AUTOSAR XML (schema 4-2-2)
# Copyright 2017 Mentor Graphics Corporation
# All rights reserved
# THIS WORK CONTAINS TRADE SECRET AND PROPRIETARY INFORMATION WHICH IS
# THE PROPERTY OF MENTOR GRAPHICS CORPORATION OR ITS LICENSORS AND IS
# SUBJECT TO LICENSE TERMS.
package /AUTOSAR/Services/Dem
  21 x client server interface, all with is-service=true:
    AgingCycle  # [SWS_Dem_00602]
      operation SetAgingCycleState: possible-error=AgingCycle/E_NOT_OK
      error E_NOT_OK: error-code=1
    CallbackClearEventAllowed  # [SWS_Dem_00620]
      operation ClearEventAllowed: possible-error=CallbackClearEventAllowed/E_NOT_OK
        arg Allowed: type=boolean, direction=OUT
      error E_NOT_OK: error-code=1
    CallbackDTCStatusChange  # [SWS_Dem_00617]
      operation DTCStatusChanged: possible-error=CallbackDTCStatusChange/E_NOT_OK
        arg DTC: type=uint32, direction=IN
        arg DTCStatusOld: type=Dem_UdsStatusByteType, direction=IN
        arg DTCStatusNew: type=Dem_UdsStatusByteType, direction=IN
      error E_NOT_OK: error-code=1
    CallbackEventDataChanged  # [SWS_Dem_00618]
      operation EventDataChanged
    CallbackEventStatusChange  # [SWS_Dem_00615]
      operation EventStatusChanged
        arg EventStatusByteOld: type=Dem_UdsStatusByteType, direction=IN
        arg EventStatusByteNew: type=Dem_UdsStatusByteType, direction=IN
    CallbackGetFaultDetectCounter  # [SWS_Dem_00622]
      operation GetFaultDetectionCounter: possible-error=CallbackGetFaultDetectCounter/E_NOT_OK
        arg FaultDetectionCounter: type=sint8, direction=OUT
      error E_NOT_OK: error-code=1
    CallbackInitMonitorForEvent  # [SWS_Dem_00613]
      operation InitMonitorForEvent: possible-error=CallbackInitMonitorForEvent/E_NOT_OK
        arg InitMonitorReason: type=Dem_InitMonitorReasonType, direction=IN
      error E_NOT_OK: error-code=1
    CddIf  # [SWS_Dem_00666]
      operation ClearDTC: possible-error=[CddIf/DEM_CLEAR_WRONG_DTC, CddIf/DEM_CLEAR_WRONG_DTCORIGIN, CddIf/DEM_CLEAR_FAILED, CddIf/DEM_CLEAR_PENDING, CddIf/DEM_CLEAR_BUSY, CddIf/DEM_CLEAR_MEMORY_ERROR]
        arg DTC: type=uint32, direction=IN
        arg DTCFormat: type=Dem_DTCFormatType, direction=IN
        arg DTCOrigin: type=Dem_DTCOriginType, direction=IN
      6 x error:
        DEM_CLEAR_WRONG_DTC: error-code=1
        DEM_CLEAR_WRONG_DTCORIGIN: error-code=2
        DEM_CLEAR_FAILED: error-code=3
        DEM_CLEAR_PENDING: error-code=4
        DEM_CLEAR_BUSY: error-code=5
        DEM_CLEAR_MEMORY_ERROR: error-code=6
    DcmIf  # [SWS_Dem_00609]
      operation DcmClearDTC: possible-error=[DcmIf/DEM_CLEAR_WRONG_DTC, DcmIf/DEM_CLEAR_WRONG_DTCORIGIN, DcmIf/DEM_CLEAR_FAILED, DcmIf/DEM_CLEAR_PENDING, DcmIf/DEM_CLEAR_BUSY, DcmIf/DEM_CLEAR_MEMORY_ERROR]
        arg DTC: type=uint32, direction=IN
        arg DTCFormat: type=Dem_DTCFormatType, direction=IN
        arg DTCOrigin: type=Dem_DTCOriginType, direction=IN
      operation DcmEnableDTCSetting: possible-error=[DEM_CONTROL_DTC_SETTING_N_OK, DEM_CONTROL_DTC_WRONG_DTCGROUP]
        arg DTCGroup: type=uint32, direction=IN
        arg DTCKind: type=Dem_DTCKindType, direction=IN
      8 x error:
        DEM_CLEAR_WRONG_DTC: error-code=1
        DEM_CLEAR_WRONG_DTCORIGIN: error-code=2
        DEM_CLEAR_FAILED: error-code=3
        DEM_CLEAR_PENDING: error-code=4
        DEM_CLEAR_BUSY: error-code=5
        DEM_CLEAR_MEMORY_ERROR: error-code=6
        DEM_CONTROL_DTC_SETTING_N_OK: error-code=1
        DEM_CONTROL_DTC_WRONG_DTCGROUP: error-code=2
    DiagnosticInfo  # [SWS_Dem_00599]
      7 x operation:
        GetEventExtendedDataRecord: possible-error=[DiagnosticInfo/E_NOT_OK, DiagnosticInfo/DEM_E_NODATAAVAILABLE, DiagnosticInfo/DEM_E_WRONG_RECORDNUMBER]
          arg RecordNumber: type=uint8, direction=IN
          arg DestBuffer: type=Dem_MaxDataValueType, direction=OUT, server-argument-impl-policy=USE-ARRAY-BASE-TYPE
        GetEventFreezeFrameData: possible-error=[DiagnosticInfo/E_NOT_OK, DiagnosticInfo/DEM_E_NODATAAVAILABLE, DiagnosticInfo/DEM_E_WRONG_RECORDNUMBER, DiagnosticInfo/DEM_E_WRONG_DIDNUMBER]
          4 x arg:
            RecordNumber: type=uint8, direction=IN
            ReportTotalRecord: type=boolean, direction=IN
            DataId: type=uint16, direction=IN
            DestBuffer: type=Dem_MaxDataValueType, direction=OUT, server-argument-impl-policy=USE-ARRAY-BASE-TYPE
        GetDTCOfEvent: possible-error=[DiagnosticInfo/E_NOT_OK, DiagnosticInfo/DEM_E_NO_DTC_AVAILABLE]
          arg DTCFormat: type=Dem_DTCFormatType, direction=IN
          arg DTCOfEvent: type=uint32, direction=OUT
        GetEventFailed: possible-error=DiagnosticInfo/E_NOT_OK
          arg EventFailed: type=boolean, direction=OUT
        GetEventStatus: possible-error=DiagnosticInfo/E_NOT_OK
          arg EventStatusByte: type=Dem_UdsStatusByteType, direction=OUT
        GetEventTested: possible-error=DiagnosticInfo/E_NOT_OK
          arg EventTested: type=boolean, direction=OUT
        GetFaultDetectionCounter: possible-error=[DiagnosticInfo/E_NOT_OK, DiagnosticInfo/DEM_E_NO_FDC_AVAILABLE]
          arg FaultDetectionCounter: type=sint8, direction=OUT
      6 x error:
        E_NOT_OK: error-code=1
        DEM_E_NO_DTC_AVAILABLE: error-code=2
        DEM_E_NO_FDC_AVAILABLE: error-code=3
        DEM_E_NODATAAVAILABLE: error-code=48
        DEM_E_WRONG_RECORDNUMBER: error-code=49
        DEM_E_WRONG_DIDNUMBER: error-code=50
    DiagnosticMonitor  # [SWS_Dem_00598]
      4 x operation, all with possible-error=DiagnosticMonitor/E_NOT_OK:
        SetEventStatus
          arg EventStatus: type=Dem_EventStatusType, direction=IN
        ResetEventStatus
        PrestoreFreezeFrame
        ClearPrestoredFreezeFrame
      error E_NOT_OK: error-code=1
    DTCSuppression  # [SWS_Dem_00608]
      operation SetDTCSuppression: possible-error=DTCSuppression/E_NOT_OK
        arg DTC: type=uint32, direction=IN
        arg DTCFormat: type=Dem_DTCFormatType, direction=IN
        arg SuppressionStatus: type=boolean, direction=IN
      error E_NOT_OK: error-code=1
    EvMemOverflowIndication  # [SWS_Dem_00607]
      operation GetEventMemoryOverflow: possible-error=EvMemOverflowIndication/E_NOT_OK
        arg OverflowIndication: type=boolean, direction=OUT
      error E_NOT_OK: error-code=1
    ExternalAgingCycle
      operation SetAgingCycleCounterValue: possible-error=ExternalAgingCycle/E_NOT_OK
        arg CounterValue: type=uint8, direction=IN
      error E_NOT_OK: error-code=1
    GeneralCallbackEventDataChanged  # [SWS_Dem_00619]
      operation EventDataChanged
        arg EventId: type=Dem_EventIdType, direction=IN
    GeneralCallbackEventStatusChange  # [SWS_Dem_00616]
      operation EventStatusChanged
        arg EventId: type=Dem_EventIdType, direction=IN
        arg EventStatusByteOld: type=Dem_UdsStatusByteType, direction=IN
        arg EventStatusByteNew: type=Dem_UdsStatusByteType, direction=IN
    GeneralDiagnosticInfo  # [SWS_Dem_00600]
      7 x operation:
        GetDTCOfEvent: possible-error=[GeneralDiagnosticInfo/E_NOT_OK, GeneralDiagnosticInfo/DEM_E_NO_DTC_AVAILABLE]
          arg EventId: type=Dem_EventIdType, direction=IN
          arg DTCFormat: type=Dem_DTCFormatType, direction=IN
          arg DTCOfEvent: type=uint32, direction=OUT
        GetEventExtendedDataRecord: possible-error=[GeneralDiagnosticInfo/E_NOT_OK, GeneralDiagnosticInfo/DEM_E_NODATAAVAILABLE, GeneralDiagnosticInfo/DEM_E_WRONG_RECORDNUMBER]
          arg EventId: type=Dem_EventIdType, direction=IN
          arg RecordNumber: type=uint8, direction=IN
          arg DestBuffer: type=Dem_MaxDataValueType, direction=OUT, server-argument-impl-policy=USE-ARRAY-BASE-TYPE
        GetEventFailed: possible-error=GeneralDiagnosticInfo/E_NOT_OK
          arg EventId: type=Dem_EventIdType, direction=IN
          arg EventFailed: type=boolean, direction=OUT
        GetEventFreezeFrameData: possible-error=[GeneralDiagnosticInfo/E_NOT_OK, GeneralDiagnosticInfo/DEM_E_NODATAAVAILABLE, GeneralDiagnosticInfo/DEM_E_WRONG_RECORDNUMBER, GeneralDiagnosticInfo/DEM_E_WRONG_DIDNUMBER]
          5 x arg:
            EventId: type=Dem_EventIdType, direction=IN
            RecordNumber: type=uint8, direction=IN
            ReportTotalRecord: type=boolean, direction=IN
            DataId: type=uint16, direction=IN
            DestBuffer: type=Dem_MaxDataValueType, direction=OUT, server-argument-impl-policy=USE-ARRAY-BASE-TYPE
        GetEventStatus: possible-error=GeneralDiagnosticInfo/E_NOT_OK
          arg EventId: type=Dem_EventIdType, direction=IN
          arg EventStatusByte: type=Dem_UdsStatusByteType, direction=OUT
        GetEventTested: possible-error=GeneralDiagnosticInfo/E_NOT_OK
          arg EventId: type=Dem_EventIdType, direction=IN
          arg EventTested: type=boolean, direction=OUT
        GetFaultDetectionCounter: possible-error=GeneralDiagnosticInfo/E_NOT_OK
          arg EventId: type=Dem_EventIdType, direction=IN
          arg FaultDetectionCounter: type=sint8, direction=OUT
      6 x error:
        E_NOT_OK: error-code=1
        DEM_E_NO_DTC_AVAILABLE: error-code=2
        DEM_E_NO_FDC_AVAILABLE: error-code=3
        DEM_E_NODATAAVAILABLE: error-code=48
        DEM_E_WRONG_RECORDNUMBER: error-code=49
        DEM_E_WRONG_DIDNUMBER: error-code=50
    IndicatorStatus  # [SWS_Dem_00606]
      operation GetIndicatorStatus: possible-error=IndicatorStatus/E_NOT_OK
        arg IndicatorStatus: type=Dem_IndicatorStatusType, direction=OUT
      error E_NOT_OK: error-code=1
    OperationCycle  # [SWS_Dem_00601]
      operation SetOperationCycleState: possible-error=OperationCycle/E_NOT_OK
        arg CycleState: type=Dem_OperationCycleStateType, direction=IN
      error E_NOT_OK: error-code=1
    PermanentClearCondition  # [VSTAR_Dem_00054]
      operation SetPermClearCondFulfilled: possible-error=PermanentClearCondition/E_NOT_OK
      error E_NOT_OK: error-code=1
    PowerTakeOff  # [SWS_Dem_00612]
      operation SetPtoStatus: possible-error=PowerTakeOff/E_NOT_OK
        arg PtoStatus: type=boolean, direction=IN
      error E_NOT_OK: error-code=1
  12 x impl type:
    Dem_DTCFormatType: compu {00=DEM_DTC_FORMAT_OBD, 11=DEM_DTC_FORMAT_UDS, 22=DEM_DTC_FORMAT_J1939} "[SWS_Dem_00933]", implementation-data-type=uint8  # [SWS_Dem_00933]
    Dem_DTCKindType: compu {1=DEM_DTC_KIND_ALL_DTCS, 2=DEM_DTC_KIND_EMISSION_REL_DTCS} "[SWS_Dem_00932]", implementation-data-type=uint8  # [SWS_Dem_00932]
    Dem_DTCOriginType: compu {1=DEM_DTC_ORIGIN_PRIMARY_MEMORY, 2=DEM_DTC_ORIGIN_MIRROR_MEMORY, 3=DEM_DTC_ORIGIN_PERMANENT_MEMORY, 4=DEM_DTC_ORIGIN_SECONDARY_MEMORY}, implementation-data-type=uint8
    Dem_EventIdType: implementation-data-type=uint16  # [SWS_Dem_00925]
    Dem_UdsStatusByteType: compu {1=DEM_UDS_STATUS_TF, 2=DEM_UDS_STATUS_TFTOC, 4=DEM_UDS_STATUS_PDTC, 8=DEM_UDS_STATUS_CDTC, 16=DEM_UDS_STATUS_TNCSLC, 32=DEM_UDS_STATUS_TFSLC, 64=DEM_UDS_STATUS_TNCTOC, 128=DEM_UDS_STATUS_WIR} "[SWS_Dem_00928]", implementation-data-type=uint8  # [SWS_Dem_00928]
    Dem_EventStatusType: compu {0=DEM_EVENT_STATUS_PASSED, 1=DEM_EVENT_STATUS_FAILED, 2=DEM_EVENT_STATUS_PREPASSED, 3=DEM_EVENT_STATUS_PREFAILED, 4=DEM_EVENT_STATUS_FDC_THRESHOLD_REACHED} "[SWS_Dem_00926]", implementation-data-type=uint8  # [SWS_Dem_00926]
    Dem_MaxDataValueType: category=ARRAY
      element ARRAYELEMENT: array-size=1, array-size-semantics=FIXED-SIZE, implementation-data-type=uint8
    Dem_IndicatorIdType: implementation-data-type=uint8
    Dem_IndicatorStatusType: compu {0=DEM_INDICATOR_OFF, 1=DEM_INDICATOR_CONTINUOUS, 2=DEM_INDICATOR_BLINKING, 3=DEM_INDICATOR_BLINK_CONT, 4=DEM_INDICATOR_SLOW_FLASH, 5=DEM_INDICATOR_FAST_FLASH, 6=DEM_INDICATOR_ON_DEMAND, 7=DEM_INDICATOR_SHORT} "[SWS_Dem_00930]", implementation-data-type=uint8  # [SWS_Dem_00930]
    Dem_InitMonitorReasonType: compu {1=DEM_INIT_MONITOR_CLEAR, 2=DEM_INIT_MONITOR_RESTART, 3=DEM_INIT_MONITOR_REENABLED, 4=DEM_INIT_MONITOR_STORAGE_REENABLED} "[SWS_Dem_00942]", implementation-data-type=uint8  # [SWS_Dem_00942]
    Dem_OperationCycleIdType: implementation-data-type=uint8
    Dem_OperationCycleStateType: compu {0=DEM_CYCLE_STATE_START, 1=DEM_CYCLE_STATE_END} "[SWS_Dem_00929]", implementation-data-type=uint8  # [SWS_Dem_00929]
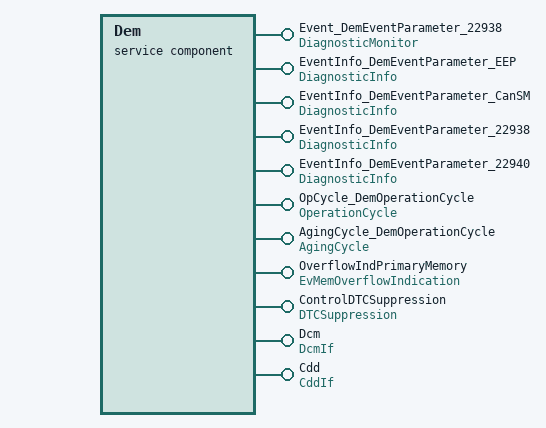
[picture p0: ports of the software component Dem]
  service sw component type Dem
    11 x provide port:
      Event_DemEventParameter_22938: provided-interface=DiagnosticMonitor
      EventInfo_DemEventParameter_EEP: provided-interface=DiagnosticInfo
      EventInfo_DemEventParameter_CanSM: provided-interface=DiagnosticInfo
      EventInfo_DemEventParameter_22938: provided-interface=DiagnosticInfo
      EventInfo_DemEventParameter_22940: provided-interface=DiagnosticInfo
      OpCycle_DemOperationCycle: provided-interface=OperationCycle
      AgingCycle_DemOperationCycle: provided-interface=AgingCycle
      OverflowIndPrimaryMemory: provided-interface=EvMemOverflowIndication
      ControlDTCSuppression: server-com-spec{operation=SetDTCSuppression, queue-length=1}, provided-interface=DTCSuppression
      Dcm: server-com-spec{operation=DcmClearDTC, queue-length=1}, provided-interface=DcmIf
      Cdd: server-com-spec{operation=ClearDTC, queue-length=1}, provided-interface=CddIf
    behavior IB_Dem: handle-termination-and-restart=NO-SUPPORT, included-data-type-set=data-type=[Dem_DTCKindType, Dem_DTCFormatType, Dem_DTCOriginType, Dem_EventStatusType, Dem_IndicatorStatusType, Dem_InitMonitorReasonType, Dem_OperationCycleStateType, Dem_UdsStatusByteType, Dem_OperationCycleIdType, Dem_IndicatorIdType]
      37 x operation invoked event:
        SES_DemEventParameter_22938: start-on-event=SetEventStatus, operation=Event_DemEventParameter_22938.SetEventStatus
        RES_DemEventParameter_22938: start-on-event=ResetEventStatus, operation=Event_DemEventParameter_22938.ResetEventStatus
        GES_DemEventParameter_EEP: start-on-event=GetEventStatus, operation=EventInfo_DemEventParameter_EEP.GetEventStatus
        GEF_DemEventParameter_EEP: start-on-event=GetEventFailed, operation=EventInfo_DemEventParameter_EEP.GetEventFailed
        GET_DemEventParameter_EEP: start-on-event=GetEventTested, operation=EventInfo_DemEventParameter_EEP.GetEventTested
        GDOE_DemEventParameter_EEP: start-on-event=GetDTCOfEvent, operation=EventInfo_DemEventParameter_EEP.GetDTCOfEvent
        GFDC_DemEventParameter_EEP: start-on-event=GetFaultDetectionCounter, operation=EventInfo_DemEventParameter_EEP.GetFaultDetectionCounter
        GEEDR_DemEventParameter_EEP: start-on-event=GetEventExtendedDataRecord, operation=EventInfo_DemEventParameter_EEP.GetEventExtendedDataRecord
        GEFFD_DemEventParameter_EEP: start-on-event=GetEventFreezeFrameData, operation=EventInfo_DemEventParameter_EEP.GetEventFreezeFrameData
        GES_DemEventParameter_CanSM: start-on-event=GetEventStatus, operation=EventInfo_DemEventParameter_CanSM.GetEventStatus
        GEF_DemEventParameter_CanSM: start-on-event=GetEventFailed, operation=EventInfo_DemEventParameter_CanSM.GetEventFailed
        GET_DemEventParameter_CanSM: start-on-event=GetEventTested, operation=EventInfo_DemEventParameter_CanSM.GetEventTested
        GDOE_DemEventParameter_CanSM: start-on-event=GetDTCOfEvent, operation=EventInfo_DemEventParameter_CanSM.GetDTCOfEvent
        GFDC_DemEventParameter_CanSM: start-on-event=GetFaultDetectionCounter, operation=EventInfo_DemEventParameter_CanSM.GetFaultDetectionCounter
        GEEDR_DemEventParameter_CanSM: start-on-event=GetEventExtendedDataRecord, operation=EventInfo_DemEventParameter_CanSM.GetEventExtendedDataRecord
        GEFFD_DemEventParameter_CanSM: start-on-event=GetEventFreezeFrameData, operation=EventInfo_DemEventParameter_CanSM.GetEventFreezeFrameData
        GES_DemEventParameter_22938: start-on-event=GetEventStatus, operation=EventInfo_DemEventParameter_22938.GetEventStatus
        GEF_DemEventParameter_22938: start-on-event=GetEventFailed, operation=EventInfo_DemEventParameter_22938.GetEventFailed
        GET_DemEventParameter_22938: start-on-event=GetEventTested, operation=EventInfo_DemEventParameter_22938.GetEventTested
        GDOE_DemEventParameter_22938: start-on-event=GetDTCOfEvent, operation=EventInfo_DemEventParameter_22938.GetDTCOfEvent
        GFDC_DemEventParameter_22938: start-on-event=GetFaultDetectionCounter, operation=EventInfo_DemEventParameter_22938.GetFaultDetectionCounter
        GEEDR_DemEventParameter_22938: start-on-event=GetEventExtendedDataRecord, operation=EventInfo_DemEventParameter_22938.GetEventExtendedDataRecord
        GEFFD_DemEventParameter_22938: start-on-event=GetEventFreezeFrameData, operation=EventInfo_DemEventParameter_22938.GetEventFreezeFrameData
        GES_DemEventParameter_22940: start-on-event=GetEventStatus, operation=EventInfo_DemEventParameter_22940.GetEventStatus
        GEF_DemEventParameter_22940: start-on-event=GetEventFailed, operation=EventInfo_DemEventParameter_22940.GetEventFailed
        GET_DemEventParameter_22940: start-on-event=GetEventTested, operation=EventInfo_DemEventParameter_22940.GetEventTested
        GDOE_DemEventParameter_22940: start-on-event=GetDTCOfEvent, operation=EventInfo_DemEventParameter_22940.GetDTCOfEvent
        GFDC_DemEventParameter_22940: start-on-event=GetFaultDetectionCounter, operation=EventInfo_DemEventParameter_22940.GetFaultDetectionCounter
        GEEDR_DemEventParameter_22940: start-on-event=GetEventExtendedDataRecord, operation=EventInfo_DemEventParameter_22940.GetEventExtendedDataRecord
        GEFFD_DemEventParameter_22940: start-on-event=GetEventFreezeFrameData, operation=EventInfo_DemEventParameter_22940.GetEventFreezeFrameData
        GEMO_Primary: start-on-event=GetEventMemoryOverflow, operation=OverflowIndPrimaryMemory.GetEventMemoryOverflow
        SOCS_DemOperationCycle: start-on-event=SetOperationCycleState, operation=OpCycle_DemOperationCycle.SetOperationCycleState
        SACS_DemOperationCycle: start-on-event=SetAgingCycleState, operation=AgingCycle_DemOperationCycle.SetAgingCycleState
        OIE_SetDTCSuppression: start-on-event=SetDTCSuppression, operation=ControlDTCSuppression.SetDTCSuppression
        OIE_DcmClearDTC: start-on-event=DcmClearDTC, operation=Dcm.DcmClearDTC
        OIE_DcmEnableDTCSetting: start-on-event=DcmEnableDTCSetting, operation=Dcm.DcmEnableDTCSetting
        OIE_CddClearDTC: start-on-event=CddClearDTC, operation=Cdd.ClearDTC
      port-api-options:
        {enable-take-address=false, indirect-api=false, port-defined-argument-value{value=EventId:3, value-type=Dem_EventIdType}, port=Event_DemEventParameter_22938}
        {enable-take-address=false, indirect-api=false, port-defined-argument-value{value=EventId:1, value-type=Dem_EventIdType}, port=EventInfo_DemEventParameter_EEP}
        {enable-take-address=false, indirect-api=false, port-defined-argument-value{value=EventId:2, value-type=Dem_EventIdType}, port=EventInfo_DemEventParameter_CanSM}
        {enable-take-address=false, indirect-api=false, port-defined-argument-value{value=EventId:3, value-type=Dem_EventIdType}, port=EventInfo_DemEventParameter_22938}
        {enable-take-address=false, indirect-api=false, port-defined-argument-value{value=EventId:4, value-type=Dem_EventIdType}, port=EventInfo_DemEventParameter_22940}
        {enable-take-address=false, indirect-api=false, port-defined-argument-value{value=DTCOrigin:DEM_DTC_ORIGIN_PRIMARY_MEMORY, value-type=Dem_DTCOriginType}, port=OverflowIndPrimaryMemory}
        {enable-take-address=false, indirect-api=false, port-defined-argument-value{value=OperationCycleId:0, value-type=uint8}, port=OpCycle_DemOperationCycle}
        {enable-take-address=false, indirect-api=false, port-defined-argument-value{value=OperationCycleId:0, value-type=uint8}, port=AgingCycle_DemOperationCycle}
      19 x runnable:
        DcmClearDTC: symbol=Dem_DcmClearDTC
        DcmEnableDTCSetting: symbol=Dem_DcmEnableDTCSetting
        CddClearDTC: symbol=Dem_ClearDTC
        MainFunction: symbol=Dem_MainFunction
        SetEventStatus: can-be-invoked-concurrently=true, symbol=Dem_SetEventStatus
        ResetEventStatus: can-be-invoked-concurrently=true, symbol=Dem_ResetEventStatus
        GetFaultDetectionCounter: can-be-invoked-concurrently=true, symbol=Dem_GetFaultDetectionCounter
        SetOperationCycleState: can-be-invoked-concurrently=true, symbol=Dem_SetOperationCycleState
        SetAgingCycleState: can-be-invoked-concurrently=true, symbol=Dem_SetAgingCycleState
        GetEventStatus: can-be-invoked-concurrently=true, symbol=Dem_GetEventStatus
        GetEventFailed: can-be-invoked-concurrently=true, symbol=Dem_GetEventFailed
        GetEventTested: can-be-invoked-concurrently=true, symbol=Dem_GetEventTested
        GetDTCOfEvent: can-be-invoked-concurrently=true, symbol=Dem_GetDTCOfEvent
        ClearPrestoredFreezeFrame: can-be-invoked-concurrently=true, symbol=Dem_ClearPrestoredFreezeFrame
        GetIndicatorStatus: can-be-invoked-concurrently=true, symbol=Dem_GetIndicatorStatus
        GetEventExtendedDataRecord: can-be-invoked-concurrently=true, symbol=Dem_GetEventExtendedDataRecord
        GetEventFreezeFrameData: can-be-invoked-concurrently=true, symbol=Dem_GetEventFreezeFrameData
        GetEventMemoryOverflow: can-be-invoked-concurrently=true, symbol=Dem_GetEventMemoryOverflow
        SetDTCSuppression: symbol=Dem_SetDTCSuppression
  swc implementation IMPL_Dem: programming-language=C, sw-version=6.1.0, swc-bsw-mapping=SwcBswMapping_Dem, vendor-id=31, behavior=IB_Dem
    code-descriptors:
      code CODE_Dem: artifact-descriptors=autosar-engineering-object={short-label=Dem, category=SWSRC}
    resource consumption RC_Dem
      memory section CODE: alignment=UNSPECIFIED, sw-addrmethod=CODE
